# DCC0 register map
Vendor: Texas Instruments
Peripheral module from a debugger description file (folder am65x).
Registers are 32-bit, access per field, reset 0x0 unless marked. A register's access mark holds for its fields unless they carry their own. Offsets are as the file gives them; lines under a group give offsets from that group; [hi:lo] are bit positions; {n}, {i} and the like mark numbered series; 'fields as' and 'values as' point back to an identical list; <NAME> marks a mode.

## DCC0
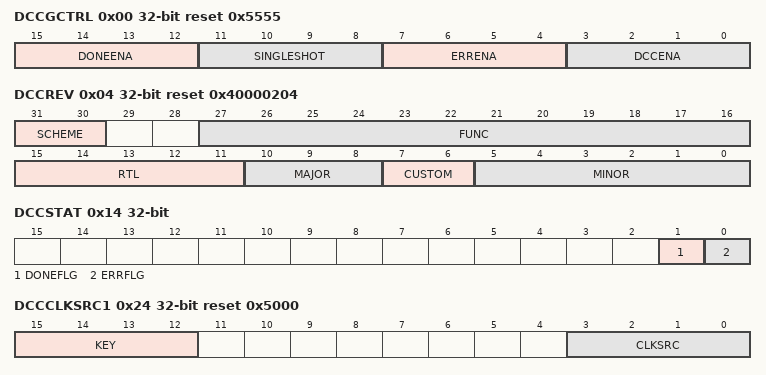
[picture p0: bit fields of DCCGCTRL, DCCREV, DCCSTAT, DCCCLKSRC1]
0x00 DCCGCTRL reset 0x5555 — DCC Global Control Register
  [15:12] DONEENA rw — The DONEENA bit enables/disables the done interrupt signal, but has no effect on the done status flag in
  [11:8] SINGLESHOT rw — The SINGLESHOT bit enables/disables repetitive operation of the DCC.
  [7:4] ERRENA rw — The ERRENA bit enables/disables the error signal.
  [3:0] DCCENA rw — The DCCENA bit starts and stops the operation of the DCC.
0x04 DCCREV ro reset 0x40000204 — DCC Revision ID
  [31:30] SCHEME — User, privilege, and debug mode (read):
  [27:16] FUNC — Reflects software-compatability. If there is no level a software compatability, a unique func number is assigned for compatible modules, the same number is maintained.
  [15:11] RTL — Incremented for releases due to spec changes or post-release design changes. Reset to 0 when either MAJOR or MINOR is incremented.
  [10:8] MAJOR — Represents major changes to the module (e.g. entirely new features are added/changed). The major revision number for this module.
  [7:6] CUSTOM — Indicates a special version of the module. May not be supported by standard software.
  [5:0] MINOR — Represents minor changes to the module (e.g. enhancements to existing features). The minor revision number for this module.
0x08 DCCCNTSEED0 — Count0 Seed Value Register
  [19:0] COUNTSEED0 rw — This field contains the seed value that gets loaded into Counter0 (clock source 0).
0x0C DCCVALIDSEED0 — Valid0 Seed Value Register
  [15:0] VALIDSEED0 rw — This field contains the seed value that gets loaded into the valid duration counter for clock source 0.
0x10 DCCCNTSEED1 — Count1 Seed Value Register
  [19:0] COUNTSEED1 rw — This field contains the seed value that gets loaded into Counter1 (clock source 1).
0x14 DCCSTAT — DCC Status Register
  [1] DONEFLG rw — Indicates when single-shot mode is complete without error. Writing a 1h to this bit clears the flag.
  [0] ERRFLG rw — Indicates whether or not an error has occurred. Writing a 1h to this bit clears the flag.
0x18 DCCCNT0 ro — Count0 Value Register
  [19:0] COUNT0 — This field contains the current value of Counter0.
0x1C DCCVALID0 ro — Valid0 Value Register
  [15:0] VALID0 — This field contains the current value of valid Counter0.
0x20 DCCCNT1 ro — Count1 Value Register
  [19:0] COUNT1 — This field contains the current value of Counter1.
0x24 DCCCLKSRC1 reset 0x5000 — Clock Source Selection Register 1
  [15:12] KEY rw — This field enables or disables clock source selection.
  [3:0] CLKSRC rw — This field specifies the clock source for COUNT1, when the KEY field enables this feature.
0x28 DCCCLKSRC0 reset 0x5 — Clock Source Selection Register 0
  [3:0] CLKSRC0 rw — This field specifies the clock source for COUNT0.
